AUTOSAR XML (schema 4-2-2)
package /ComponentTypes
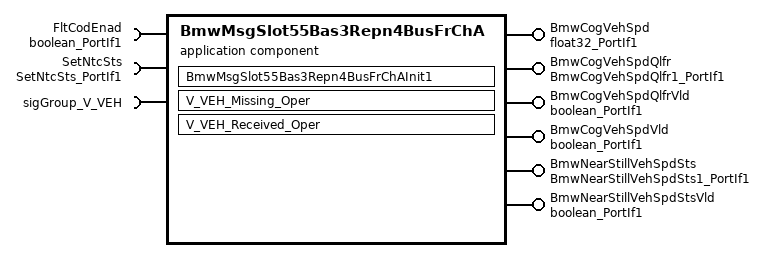
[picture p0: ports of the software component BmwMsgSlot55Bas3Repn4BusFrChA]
  application sw component type BmwMsgSlot55Bas3Repn4BusFrChA
    6 x provide port:
      BmwCogVehSpd: nonqueued-sender-com-spec{data-element=Val, init-value=0}, provided-interface=float32_PortIf1
      BmwCogVehSpdQlfr: nonqueued-sender-com-spec{data-element=Val, init-value=15}, provided-interface=BmwCogVehSpdQlfr1_PortIf1
      BmwCogVehSpdQlfrVld: nonqueued-sender-com-spec{data-element=Logl, init-value=0}, provided-interface=boolean_PortIf1
      BmwCogVehSpdVld: nonqueued-sender-com-spec{data-element=Logl, init-value=0}, provided-interface=boolean_PortIf1
      BmwNearStillVehSpdSts: nonqueued-sender-com-spec{data-element=Val, init-value=15}, provided-interface=BmwNearStillVehSpdSts1_PortIf1
      BmwNearStillVehSpdStsVld: nonqueued-sender-com-spec{data-element=Logl, init-value=0}, provided-interface=boolean_PortIf1
    require port FltCodEnad: nonqueued-receiver-com-spec{data-element=Logl, filter=data-filter-type=ALWAYS, init-value=1}, required-interface=boolean_PortIf1
    require port SetNtcSts: client-com-spec=Oper, required-interface=SetNtcSts_PortIf1
    require port sigGroup_V_VEH: nonqueued-receiver-com-spec{data-element=sigGroup_V_VEH, uses-end-to-end-protection=true, alive-timeout=0.02, enable-update=true, filter=data-filter-type=ALWAYS, init-value=fields=[V_VEH_COG:0, ST_V_VEH_NSS:0, QU_V_VEH_COG:0, ALIV_V_VEH:0, V_VEH_dummy_39_39:1, DVCO_VEH:0, CRC_V_VEH:0]}, required-interface=sigGroup_V_VEH
    behavior BmwMsgSlot55Bas3Repn4BusFrChA_InternalBehavior
      ar-typed-per-instance-memorys:
        17 x data, all with sw-calibration-access=READ-ONLY:
          AlvFaildCnt: type=uint8
          AlvPassdCnt: type=uint8
          BmwCogVehSpdPrev: type=float32
          BmwCogVehSpdQlfrPrev: type=BmwCogVehSpdQlfr1
          BmwNearStillVehSpdStsPrev: type=BmwNearStillVehSpdSts1
          CrcFaildCnt: type=uint8
          CrcPassdCnt: type=uint8
          Dummy_PIM1: type=QU_V_VEH_COG1
          Dummy_PIM2: type=ST_V_VEH_NSS1
          MissMsgCnt: type=uint8
          QlfrCogFaildCnt: type=uint8
          QlfrCogPassdCnt: type=uint8
          RxdMsgCnt: type=uint8
          StVehNearStillFailCnt: type=uint8
          StVehNearStillPassCnt: type=uint8
          VehCogFaildCnt: type=uint8
          VehCogPassdCnt: type=uint8
      init event BmwMsgSlot55Bas3Repn4BusFrChA_InitEvent: start-on-event=BmwMsgSlot55Bas3Repn4BusFrChAInit1
      data receive error event DRET_V_VEH_Missing_Oper_sigGroup_V_VEH_sigGroup_V_VEH: start-on-event=V_VEH_Missing_Oper, data=sigGroup_V_VEH.sigGroup_V_VEH
      data received event DRT_V_VEH_Received_Oper_sigGroup_V_VEH_sigGroup_V_VEH: start-on-event=V_VEH_Received_Oper, data=sigGroup_V_VEH.sigGroup_V_VEH
      port-api-options:
        enable-take-address=false, error-handling=NO-TRANSFORMER-ERROR-HANDLING, indirect-api=false, port=BmwCogVehSpd
        enable-take-address=false, error-handling=NO-TRANSFORMER-ERROR-HANDLING, indirect-api=false, port=BmwCogVehSpdQlfr
        enable-take-address=false, error-handling=NO-TRANSFORMER-ERROR-HANDLING, indirect-api=false, port=BmwCogVehSpdQlfrVld
        enable-take-address=false, error-handling=NO-TRANSFORMER-ERROR-HANDLING, indirect-api=false, port=BmwCogVehSpdVld
        enable-take-address=false, error-handling=NO-TRANSFORMER-ERROR-HANDLING, indirect-api=false, port=BmwNearStillVehSpdSts
        enable-take-address=false, error-handling=NO-TRANSFORMER-ERROR-HANDLING, indirect-api=false, port=BmwNearStillVehSpdStsVld
        enable-take-address=false, error-handling=NO-TRANSFORMER-ERROR-HANDLING, indirect-api=false, port=FltCodEnad
        enable-take-address=false, error-handling=NO-TRANSFORMER-ERROR-HANDLING, indirect-api=false, port=SetNtcSts
        enable-take-address=false, error-handling=NO-TRANSFORMER-ERROR-HANDLING, indirect-api=false, port=sigGroup_V_VEH
      runnable BmwMsgSlot55Bas3Repn4BusFrChAInit1
      runnable V_VEH_Missing_Oper
        data-receive-point-by-arguments:
          access REC_FltCodEnad_Logl: accessed-variable=FltCodEnad.Logl
        data-send-points:
          6 x access:
            SEND_BmwCogVehSpd_Val: accessed-variable=BmwCogVehSpd.Val
            SEND_BmwCogVehSpdQlfr_Val: accessed-variable=BmwCogVehSpdQlfr.Val
            SEND_BmwCogVehSpdQlfrVld_Logl: accessed-variable=BmwCogVehSpdQlfrVld.Logl
            SEND_BmwCogVehSpdVld_Logl: accessed-variable=BmwCogVehSpdVld.Logl
            SEND_BmwNearStillVehSpdSts_Val: accessed-variable=BmwNearStillVehSpdSts.Val
            SEND_BmwNearStillVehSpdStsVld_Logl: accessed-variable=BmwNearStillVehSpdStsVld.Logl
        sync call SC_SetNtcSts_Oper: operation=SetNtcSts.Oper, timeout=0
      runnable V_VEH_Received_Oper
        data-receive-point-by-arguments:
          access REC_FltCodEnad_Logl: accessed-variable=FltCodEnad.Logl
          access REC_sigGroup_V_VEH_sigGroup_V_VEH: accessed-variable=sigGroup_V_VEH.sigGroup_V_VEH
        data-send-points:
          6 x access:
            SEND_BmwCogVehSpd_Val: accessed-variable=BmwCogVehSpd.Val
            SEND_BmwCogVehSpdQlfr_Val: accessed-variable=BmwCogVehSpdQlfr.Val
            SEND_BmwCogVehSpdQlfrVld_Logl: accessed-variable=BmwCogVehSpdQlfrVld.Logl
            SEND_BmwCogVehSpdVld_Logl: accessed-variable=BmwCogVehSpdVld.Logl
            SEND_BmwNearStillVehSpdSts_Val: accessed-variable=BmwNearStillVehSpdSts.Val
            SEND_BmwNearStillVehSpdStsVld_Logl: accessed-variable=BmwNearStillVehSpdStsVld.Logl
        sync call SC_SetNtcSts_Oper: operation=SetNtcSts.Oper, timeout=0
  swc implementation BmwMsgSlot55Bas3Repn4BusFrChA_Implementation: behavior=BmwMsgSlot55Bas3Repn4BusFrChA_InternalBehavior
    code-descriptors:
      code Default: artifact-descriptors=autosar-engineering-object={short-label=Default, category=SWSRC}
